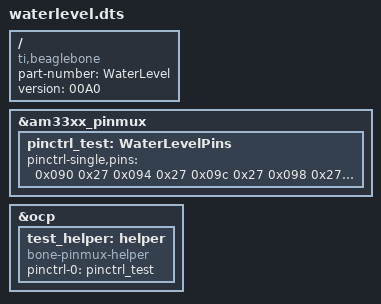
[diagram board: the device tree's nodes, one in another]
/*
* Copyright (C) 2012 Texas Instruments Incorporated - http://www.ti.com/
*
* This program is free software; you can redistribute it and/or modify
* it under the terms of the GNU General Purpose License Version 2 as
* published by the Free Software Foundation
*
* Original from: github.com/jadonk/validation-scripts/blob/master/test-capemgr/
*
* Modified by Derek Molloy for the example on www.derekmolloy.ie
* that maps GPIO pins for the example
*/

/dts-v1/;
/plugin/;

/{
       compatible = "ti,beaglebone", "ti,beaglebone-black";
       part-number = "WaterLevel";
       version = "00A0";

       fragment@0 {
             target = <&am33xx_pinmux>;

             __overlay__ {
                  pinctrl_test: WaterLevelPins {
			pinctrl-single,pins = <

				0x090 0x27
				0x094 0x27
				0x09c 0x27
				0x098 0x27
				0x034 0x27
				0x030 0x27
				0x024 0x27
				0x028 0x27
				0x03c 0x27
				0x038 0x27

			>;
		  };
             };
       };

       fragment@1 {
		target = <&ocp>;
		__overlay__ {
			test_helper: helper {
				compatible = "bone-pinmux-helper";
				pinctrl-names = "default";
				pinctrl-0 = <&pinctrl_test>;
				status = "okay";
			};
		};
	};
};
